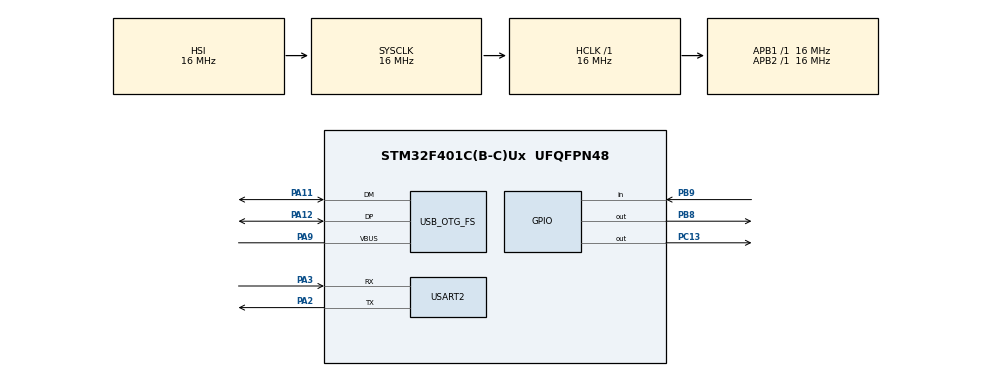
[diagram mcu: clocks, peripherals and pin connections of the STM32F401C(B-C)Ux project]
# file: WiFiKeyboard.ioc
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Mcu.Family=STM32F4
Mcu.Name=STM32F401C(B-C)Ux
Mcu.Package=UFQFPN48
NVIC.OTG_FS_IRQn=true\:0\:0\:false\:false\:true\:false\:true
NVIC.PriorityGroup=NVIC_PRIORITYGROUP_4
PA11.Mode=Host_Only
PA11.Signal=USB_OTG_FS_DM
PA12.Mode=Host_Only
PA12.Signal=USB_OTG_FS_DP
PA2.Mode=Asynchronous
PA2.Signal=USART2_TX
PA3.Mode=Asynchronous
PA3.Signal=USART2_RX
PA9.Mode=Activate_VBUS
PA9.Signal=USB_OTG_FS_VBUS
PB8.Signal=GPIO_Output
PB9.Signal=GPIO_Input
PC13-ANTI_TAMP.Signal=GPIO_Output
PC14-OSC32_IN.Mode=LSE-External-Oscillator
PC14-OSC32_IN.Signal=RCC_OSC32_IN
PC15-OSC32_OUT.Mode=LSE-External-Oscillator
PC15-OSC32_OUT.Signal=RCC_OSC32_OUT
PH0\ -\ OSC_IN.Mode=HSE-External-Oscillator
PH0\ -\ OSC_IN.Signal=RCC_OSC_IN
PH1\ -\ OSC_OUT.Mode=HSE-External-Oscillator
PH1\ -\ OSC_OUT.Signal=RCC_OSC_OUT
ProjectManager.HeapSize=0x200
ProjectManager.StackSize=0x400
ProjectManager.TargetToolchain=STM32CubeIDE
RCC.48MHZClocksFreq_Value=48000000
RCC.AHBFreq_Value=16000000
RCC.APB1Freq_Value=16000000
RCC.APB2Freq_Value=16000000
RCC.CortexFreq_Value=16000000
RCC.HSE_VALUE=25000000
RCC.HSI_VALUE=16000000
RCC.PLLM=15
RCC.PLLN=144
RCC.PLLQ=5
RCC.SYSCLKFreq_VALUE=16000000
RCC.VCOOutputFreq_Value=240000000
USART2.VirtualMode=VM_ASYNC
USB_HOST.BSP.number=1
USB_HOST.USBH_HandleTypeDef=hUsbHostFS
USB_HOST.VirtualModeFS=Hid
USB_HOST0.BSP.STBoard=false
USB_HOST0.BSP.api=Unknown
USB_HOST0.BSP.i2caddr=0
USB_HOST0.BSP.instance=PB8
USB_HOST0.BSP.ip=GPIO
USB_HOST0.BSP.mode=Output
USB_HOST0.BSP.name=Drive_VBUS_FS
USB_HOST0.BSP.solution=PB8
USB_OTG_FS.VirtualMode=Host_Only
USB_OTG_FS.phy_itface=HCD_PHY_EMBEDDED
VP_USB_HOST_VS_USB_HOST_HID_FS.Mode=HID_FS
board=custom

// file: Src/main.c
/* USER CODE BEGIN Header */
/**
  ******************************************************************************
  * @file           : main.c
  * @brief          : Main program body
  ******************************************************************************
  * @attention
  *
  * <h2><center>&copy; Copyright (c) 2020 STMicroelectronics.
  * All rights reserved.</center></h2>
  *
  * This software component is licensed by ST under Ultimate Liberty license
  * SLA0044, the "License"; You may not use this file except in compliance with
  * the License. You may obtain a copy of the License at:
  *                             www.st.com/SLA0044
  *
  ******************************************************************************
  */
/* USER CODE END Header */

#include "main.h"
#include "usart.h"
#include "usb_host.h"
#include "gpio.h"
#include "usbh_hid.h"

void SystemClock_Config(void);
void MX_USB_HOST_Process(void);

int main(void)
{

  /* MCU Configuration--------------------------------------------------------*/

  /* Reset of all peripherals, Initializes the Flash interface and the Systick. */
  HAL_Init();

  /* Configure the system clock */
  SystemClock_Config();

  /* Initialize all configured peripherals */
  GPIO_Init();
  MX_USART2_UART_Init();
  MX_USB_HOST_Init();

  while (1)
  {

    /* USER CODE END WHILE */
    MX_USB_HOST_Process();

    if(USBH_HID_GetDeviceType(&hUsbHostFS) == HID_KEYBOARD)  {
    	GPIO_LED_set();

    	HID_KEYBD_Info_TypeDef* k_pinfo = USBH_HID_GetKeybdInfo(&hUsbHostFS	);

    	if(k_pinfo != NULL){
    		/* Sending decoded ascii key. */
    		char buff[] = "\n   ";
    		buff[1] = USBH_HID_GetASCIICode(k_pinfo);
    		UART_TX((uint8_t*)buff, sizeof(buff));

    		/* Sending keyboard report */
    		UART_TX((uint8_t*)k_pinfo, sizeof(HID_KEYBD_Info_TypeDef));
    	}
	}else{
		GPIO_LED_clear();
	}
  }
}

void SystemClock_Config(void)
{
  RCC_OscInitTypeDef RCC_OscInitStruct = {0};
  RCC_ClkInitTypeDef RCC_ClkInitStruct = {0};

  /** Configure the main internal regulator output voltage
  */
  __HAL_RCC_PWR_CLK_ENABLE();
  __HAL_PWR_VOLTAGESCALING_CONFIG(PWR_REGULATOR_VOLTAGE_SCALE2);
  /** Initializes the CPU, AHB and APB busses clocks
  */
  RCC_OscInitStruct.OscillatorType = RCC_OSCILLATORTYPE_HSI|RCC_OSCILLATORTYPE_HSE;
  RCC_OscInitStruct.HSEState = RCC_HSE_ON;
  RCC_OscInitStruct.HSIState = RCC_HSI_ON;
  RCC_OscInitStruct.HSICalibrationValue = RCC_HSICALIBRATION_DEFAULT;
  RCC_OscInitStruct.PLL.PLLState = RCC_PLL_ON;
  RCC_OscInitStruct.PLL.PLLSource = RCC_PLLSOURCE_HSE;
  RCC_OscInitStruct.PLL.PLLM = 15;
  RCC_OscInitStruct.PLL.PLLN = 144;
  RCC_OscInitStruct.PLL.PLLP = RCC_PLLP_DIV2;
  RCC_OscInitStruct.PLL.PLLQ = 5;
  if (HAL_RCC_OscConfig(&RCC_OscInitStruct) != HAL_OK)
  {
    Error_Handler();
  }
  /** Initializes the CPU, AHB and APB busses clocks
  */
  RCC_ClkInitStruct.ClockType = RCC_CLOCKTYPE_HCLK|RCC_CLOCKTYPE_SYSCLK
                              |RCC_CLOCKTYPE_PCLK1|RCC_CLOCKTYPE_PCLK2;
  RCC_ClkInitStruct.SYSCLKSource = RCC_SYSCLKSOURCE_HSI;
  RCC_ClkInitStruct.AHBCLKDivider = RCC_SYSCLK_DIV1;
  RCC_ClkInitStruct.APB1CLKDivider = RCC_HCLK_DIV1;
  RCC_ClkInitStruct.APB2CLKDivider = RCC_HCLK_DIV1;

  if (HAL_RCC_ClockConfig(&RCC_ClkInitStruct, FLASH_LATENCY_0) != HAL_OK)
  {
    Error_Handler();
  }
}

void Error_Handler(void)
{
  /* USER CODE BEGIN Error_Handler_Debug */
  /* User can add his own implementation to report the HAL error return state */
	while(1){
		GPIO_LED_toggle();
		HAL_Delay(200);
	}
  /* USER CODE END Error_Handler_Debug */
}

/************************ (C) COPYRIGHT STMicroelectronics *****END OF FILE****/
